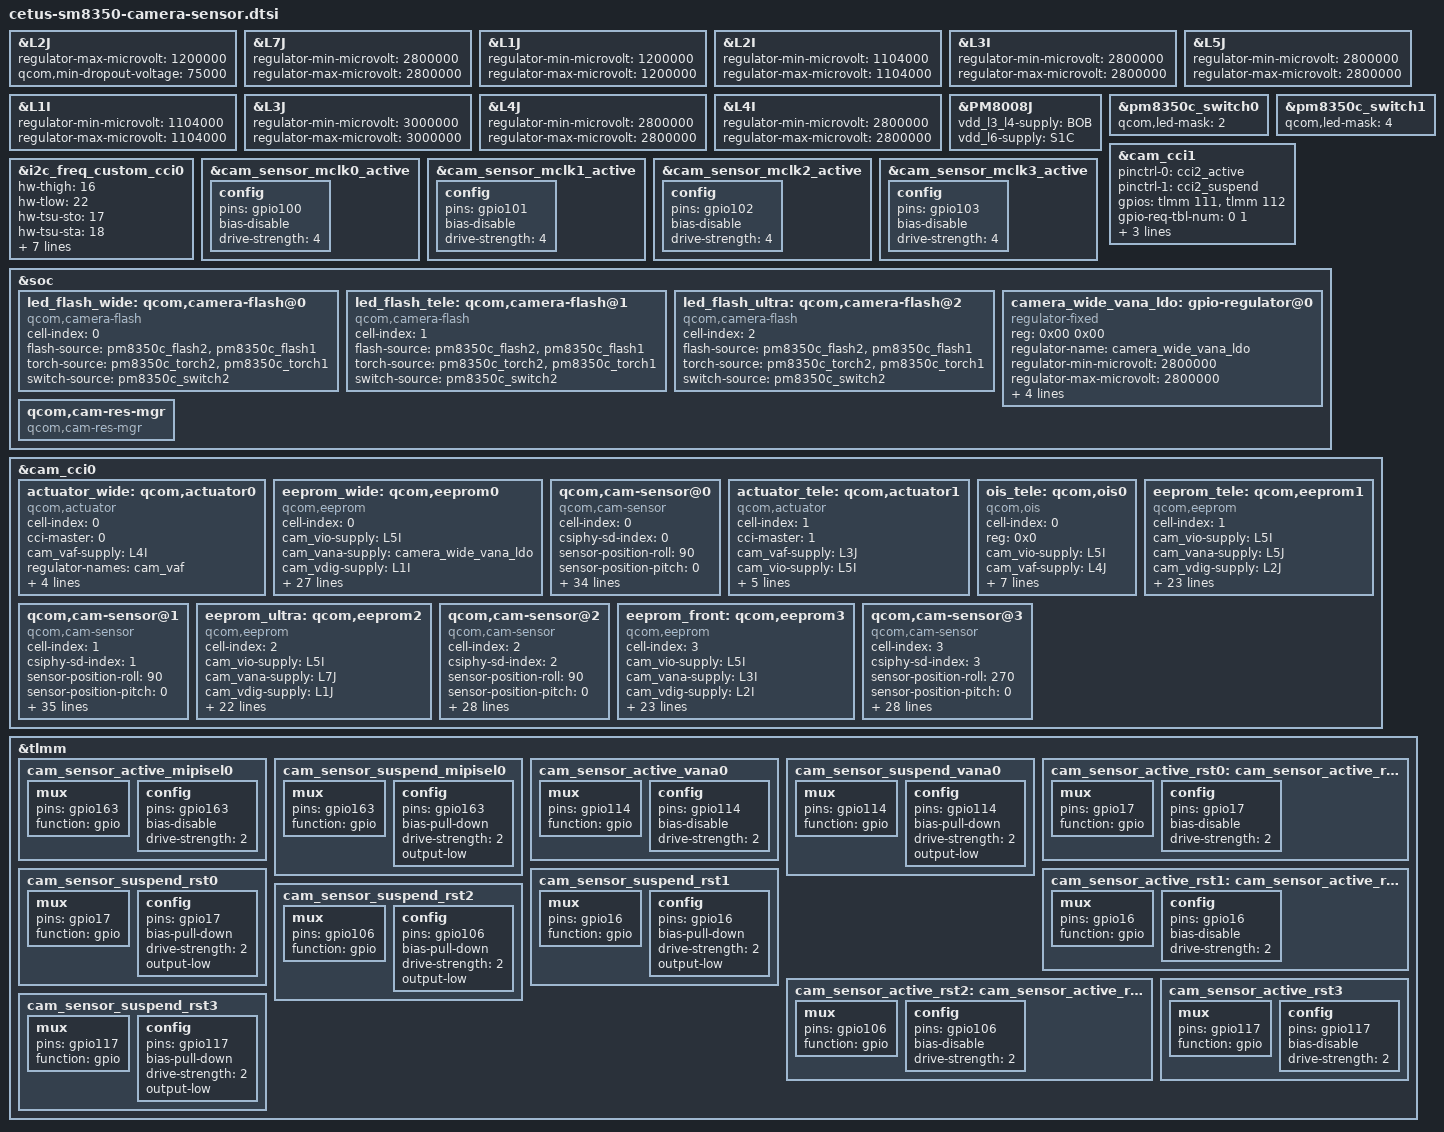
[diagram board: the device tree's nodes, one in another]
#include <dt-bindings/clock/qcom,camcc-lahaina.h>

&L2J {
	regulator-max-microvolt = <1200000>;
	qcom,min-dropout-voltage = <75000>;
};

&L7J {
	regulator-min-microvolt = <2800000>;
	regulator-max-microvolt = <2800000>;
};

&L1J {
	regulator-min-microvolt = <1200000>;
	regulator-max-microvolt = <1200000>;
};

&L2I {
	regulator-min-microvolt = <1104000>;
	regulator-max-microvolt = <1104000>;
};

&L3I {
	regulator-min-microvolt = <2800000>;
	regulator-max-microvolt = <2800000>;
};

&L5J {
	regulator-min-microvolt = <2800000>;
	regulator-max-microvolt = <2800000>;
};

&L1I {
	regulator-min-microvolt = <1104000>;
	regulator-max-microvolt = <1104000>;
};

&L3J {
	regulator-min-microvolt = <3000000>;
	regulator-max-microvolt = <3000000>;
};

&L4J {
	regulator-min-microvolt = <2800000>;
	regulator-max-microvolt = <2800000>;
};

&L4I {
	regulator-min-microvolt = <2800000>;
	regulator-max-microvolt = <2800000>;
};

&PM8008J {
	vdd_l3_l4-supply = <&BOB>;
	vdd_l6-supply = <&S1C>;
};

&pm8350c_switch0 {
	qcom,led-mask = <2>; /* Channels 1 & 2 */
};

&pm8350c_switch1 {
	qcom,led-mask = <4>; /* Channels 2 & 3 */
};

&cam_cci1 {
	pinctrl-0 = <&cci2_active>;
	pinctrl-1 = <&cci2_suspend>;
	gpios = <&tlmm 111 0>,
		<&tlmm 112 0>;
	gpio-req-tbl-num = <0 1>;
	gpio-req-tbl-flags = <1 1>;
	gpio-req-tbl-label = "CCI_I2C_DATA2",
			"CCI_I2C_CLK2";
};

&i2c_freq_custom_cci0 {
	hw-thigh = <16>;
	hw-tlow = <22>;
	hw-tsu-sto = <17>;
	hw-tsu-sta = <18>;
	hw-thd-dat = <16>;
	hw-thd-sta = <15>;
	hw-tbuf = <24>;
	hw-scl-stretch-en = <1>;
	hw-trdhld = <3>;
	hw-tsp = <3>;
	cci-clk-src = <37500000>;
	status = "ok";
};

&cam_sensor_mclk0_active {
	/* MCLK0 */
	config {
		pins = "gpio100";
		bias-disable; /* No PULL */
		drive-strength = <4>; /* 4 MA */
	};
};

&cam_sensor_mclk1_active {
	/* MCLK1 */
	config {
		pins = "gpio101";
		bias-disable; /* No PULL */
		drive-strength = <4>; /* 4 MA */
	};
};

&cam_sensor_mclk2_active {
	/* MCLK2 */
	config {
		pins = "gpio102";
		bias-disable; /* No PULL */
		drive-strength = <4>; /* 4 MA */
	};
};

&cam_sensor_mclk3_active {
	/* MCLK3 */
	config {
		pins = "gpio103";
		bias-disable; /* No PULL */
		drive-strength = <4>; /* 4 MA */
	};
};

&soc {
	led_flash_wide: qcom,camera-flash@0 {
		cell-index = <0>;
		compatible = "qcom,camera-flash";
		flash-source = <&pm8350c_flash2 &pm8350c_flash1>;
		torch-source = <&pm8350c_torch2 &pm8350c_torch1>;
		switch-source = <&pm8350c_switch2>;
		status = "ok";
	};

	led_flash_tele: qcom,camera-flash@1 {
		cell-index = <1>;
		compatible = "qcom,camera-flash";
		flash-source = <&pm8350c_flash2 &pm8350c_flash1>;
		torch-source = <&pm8350c_torch2 &pm8350c_torch1>;
		switch-source = <&pm8350c_switch2>;
		status = "ok";
	};

	led_flash_ultra: qcom,camera-flash@2 {
		cell-index = <2>;
		compatible = "qcom,camera-flash";
		flash-source = <&pm8350c_flash2 &pm8350c_flash1>;
		torch-source = <&pm8350c_torch2 &pm8350c_torch1>;
		switch-source = <&pm8350c_switch2>;
		status = "ok";
	};

	camera_wide_vana_ldo: gpio-regulator@0 {
		compatible = "regulator-fixed";
		reg = <0x00 0x00>;
		regulator-name = "camera_wide_vana_ldo";
		regulator-min-microvolt = <2800000>;
		regulator-max-microvolt = <2800000>;
		regulator-enable-ramp-delay = <135>;
		enable-active-high;
		gpio = <&tlmm 114 0>;
		vin-supply = <&pm8350c_bob>;
	};

	qcom,cam-res-mgr {
		compatible = "qcom,cam-res-mgr";
		//shared-gpios = <409>;
		//pinctrl-names = "cam_res_mgr_default", "cam_res_mgr_suspend";
		//pinctrl-0 = <&cam_sensor_mclk1_active>;
		//pinctrl-1 = <&cam_sensor_mclk1_suspend>;
		//status = "ok";
	};
};

&cam_cci0 {
	actuator_wide: qcom,actuator0 {
		cell-index = <0>;
		compatible = "qcom,actuator";
		cci-master = <0>;
		cam_vaf-supply = <&L4I>;
		regulator-names = "cam_vaf";
		rgltr-cntrl-support;
		rgltr-min-voltage = <2800000>;
		rgltr-max-voltage = <2800000>;
		rgltr-load-current = <100000>;
		status = "ok";
	};

	eeprom_wide: qcom,eeprom0 {
		cell-index = <0>;
		compatible = "qcom,eeprom";
		cam_vio-supply = <&L5I>;
		cam_vana-supply = <&camera_wide_vana_ldo>;
		cam_vdig-supply = <&L1I>;
		cam_clk-supply = <&cam_cc_titan_top_gdsc>;
		regulator-names = "cam_vio", "cam_vana", "cam_vdig","cam_clk";
		rgltr-cntrl-support;
		pwm-switch;
		rgltr-min-voltage = <1800000 2800000 1104000 0>;
		rgltr-max-voltage = <1800000 2800000 1104000 0>;
		rgltr-load-current = <120000 2000000 1200000 0>;
		gpio-no-mux = <0>;
		pinctrl-names = "cam_default", "cam_suspend";
		pinctrl-0 = <&cam_sensor_mclk0_active
			&cam_sensor_active_rst0
			&cam_sensor_active_mipisel0>;
		pinctrl-1 = <&cam_sensor_mclk0_suspend
			&cam_sensor_suspend_rst0
			&cam_sensor_suspend_mipisel0>;
		gpios = <&tlmm 100 0>,
			<&tlmm 17 0>,
			<&tlmm 163 0>;
		gpio-reset = <1>;
		gpio-custom1 = <2>;
		gpio-req-tbl-num = <0 1 2>;
		gpio-req-tbl-flags = <1 0 0>;
		gpio-req-tbl-label = "CAMIF_MCLK0",
				"CAM_RESET0",
				"CAM_MIPISEL0";
		sensor-mode = <0>;
		cci-master = <0>;
		status = "ok";
		clocks = <&clock_camcc CAM_CC_MCLK0_CLK>;
		clock-names = "cam_clk";
		clock-cntl-level = "nominal";
		clock-rates = <19200000>;
	};

	/*  Wide sensor */
	qcom,cam-sensor@0 {
		cell-index = <0>;
		compatible = "qcom,cam-sensor";
		csiphy-sd-index = <0>;
		sensor-position-roll = <90>;
		sensor-position-pitch = <0>;
		sensor-position-yaw = <180>;
		actuator-src = <&actuator_wide>;
		eeprom-src = <&eeprom_wide>;
		led-flash-src = <&led_flash_wide>;
		cam_vio-supply = <&L5I>;
		cam_vana-supply = <&camera_wide_vana_ldo>;
		cam_vdig-supply = <&L1I>;
		cam_clk-supply = <&cam_cc_titan_top_gdsc>;
		regulator-names = "cam_vio", "cam_vana", "cam_vdig","cam_clk";
		rgltr-cntrl-support;
		pwm-switch;
		rgltr-min-voltage = <1800000 2800000 1104000 0>;
		rgltr-max-voltage = <1800000 2800000 1104000 0>;
		rgltr-load-current = <120000 2000000 1200000 0>;
		gpio-no-mux = <0>;
		pinctrl-names = "cam_default", "cam_suspend";
		pinctrl-0 = <&cam_sensor_mclk0_active
			&cam_sensor_active_rst0
			&cam_sensor_active_mipisel0>;
		pinctrl-1 = <&cam_sensor_mclk0_suspend
			&cam_sensor_suspend_rst0
			&cam_sensor_suspend_mipisel0>;
		gpios = <&tlmm 100 0>,
			<&tlmm 17 0>,
			<&tlmm 163 0>;
		gpio-reset = <1>;
		gpio-custom1 = <2>;
		gpio-req-tbl-num = <0 1 2>;
		gpio-req-tbl-flags = <1 0 0>;
		gpio-req-tbl-label = "CAMIF_MCLK0",
				"CAM_RESET0",
				"CAM_MIPISEL0";
		sensor-mode = <0>;
		cci-master = <0>;
		status = "ok";
		clocks = <&clock_camcc CAM_CC_MCLK0_CLK>;
		clock-names = "cam_clk";
		clock-cntl-level = "nominal";
		clock-rates = <19200000>;
	};

	actuator_tele: qcom,actuator1 {
		cell-index = <1>;
		compatible = "qcom,actuator";
		cci-master = <1>;
		cam_vaf-supply = <&L3J>;
		cam_vio-supply = <&L5I>;
		regulator-names = "cam_vaf", "cam_vio";
		rgltr-cntrl-support;
		rgltr-min-voltage = <3000000 1800000>;
		rgltr-max-voltage = <3000000 1800000>;
		rgltr-load-current = <300000 10000>;
		status = "ok";
	};

	ois_tele: qcom,ois0 {
		cell-index = <0>;
		reg = <0x0>;
		compatible = "qcom,ois";
		cam_vio-supply = <&L5I>;
		cam_vaf-supply = <&L4J>;
		cam_clk-supply = <&cam_cc_titan_top_gdsc>;
		regulator-names = "cam_vio", "cam_vaf", "cam_clk";
		rgltr-min-voltage = <1800000 2800000 0>;
		rgltr-max-voltage = <1800000 2800000 0>;
		rgltr-load-current = <10000 280000 0>;
		//use-shared-clk;
		//gpio-no-mux = <0>;
		//gpios = <&tlmm 101 0>;
		//gpio-req-tbl-num = <0>;
		//gpio-req-tbl-flags = <1>;
		//gpio-req-tbl-label = "CAMIF_MCLK1";
		//clocks = <&clock_camcc CAM_CC_MCLK1_CLK>;
		//clock-names = "cam_clk";
		//clock-cntl-level = "nominal";
		//clock-rates = <19200000>;
		rgltr-cntrl-support;
		cci-master = <1>;
		status = "ok";
	};

	eeprom_tele: qcom,eeprom1 {
		cell-index = <1>;
		compatible = "qcom,eeprom";
		cam_vio-supply = <&L5I>;
		cam_vana-supply = <&L5J>;
		cam_vdig-supply = <&L2J>;
		cam_clk-supply = <&cam_cc_titan_top_gdsc>;
		regulator-names = "cam_vio", "cam_vana", "cam_vdig","cam_clk";
		rgltr-cntrl-support;
		pwm-switch;
		rgltr-min-voltage = <1800000 2800000 1200000 0>;
		rgltr-max-voltage = <1800000 2800000 1200000 0>;
		rgltr-load-current = <120000 80000 1200000 0>;
		gpio-no-mux = <0>;
		pinctrl-names = "cam_default", "cam_suspend";
		pinctrl-0 = <&cam_sensor_mclk1_active
			&cam_sensor_active_rst1>;
		pinctrl-1 = <&cam_sensor_mclk1_suspend
			&cam_sensor_suspend_rst1>;
		gpios = <&tlmm 101 0>,
			<&tlmm 16 0>;
		gpio-reset = <1>;
		gpio-req-tbl-num = <0 1>;
		gpio-req-tbl-flags = <1 0>;
		gpio-req-tbl-label = "CAMIF_MCLK1",
				"CAM_RESET1";
		sensor-mode = <0>;
		cci-master = <1>;
		status = "ok";
		clocks = <&clock_camcc CAM_CC_MCLK1_CLK>;
		clock-names = "cam_clk";
		clock-cntl-level = "nominal";
		clock-rates = <19200000>;
	};

	/*  Tele sensor */
	qcom,cam-sensor@1 {
		cell-index = <1>;
		compatible = "qcom,cam-sensor";
		csiphy-sd-index = <1>;
		sensor-position-roll = <90>;
		sensor-position-pitch = <0>;
		sensor-position-yaw = <180>;
		eeprom-src = <&eeprom_tele>;
		actuator-src = <&actuator_tele>;
		ois-src = <&ois_tele>;
		led-flash-src = <&led_flash_tele>;
		cam_vio-supply = <&L5I>;
		cam_vana-supply = <&L5J>;
		cam_vdig-supply = <&L2J>;
		cam_vaf-supply = <&L4J>;
		cam_clk-supply = <&cam_cc_titan_top_gdsc>;
		//cam_bob-supply = <&pm8350c_bob>;
		regulator-names = "cam_vio", "cam_vana", "cam_vdig", "cam_vaf",
				 "cam_clk";
		rgltr-cntrl-support;
		pwm-switch;
		rgltr-min-voltage = <1800000 2800000 1200000 2800000 0>;
		rgltr-max-voltage = <1800000 2800000 1200000 2800000 0>;
		rgltr-load-current = <120000 80000 1200000 280000 0>;
		gpio-no-mux = <0>;
		//use-shared-clk;
		pinctrl-names = "cam_default", "cam_suspend";
		pinctrl-0 = <&cam_sensor_active_rst1
                        &cam_sensor_mclk1_active>;
		pinctrl-1 = <&cam_sensor_suspend_rst1
                        &cam_sensor_mclk1_suspend>;
		gpios = <&tlmm 101 0>,
			<&tlmm 16 0>;
		gpio-reset = <1>;
		gpio-req-tbl-num = <0 1>;
		gpio-req-tbl-flags = <1 0>;
		gpio-req-tbl-label = "CAMIF_MCLK1",
				"CAM_RESET1";
		sensor-mode = <0>;
		cci-master = <1>;
		status = "ok";
		clocks = <&clock_camcc CAM_CC_MCLK1_CLK>;
		clock-names = "cam_clk";
		clock-cntl-level = "nominal";
		clock-rates = <19200000>;
	};

	eeprom_ultra: qcom,eeprom2 {
		cell-index = <2>;
		compatible = "qcom,eeprom";
		cam_vio-supply = <&L5I>;
		cam_vana-supply = <&L7J>;
		cam_vdig-supply = <&L1J>;
		cam_clk-supply = <&cam_cc_titan_top_gdsc>;
		regulator-names = "cam_vio", "cam_vdig","cam_vana", "cam_clk";
		rgltr-cntrl-support;
		rgltr-min-voltage = <1800000 1200000 2800000 0>;
		rgltr-max-voltage = <1800000 1200000 2800000 0>;
		rgltr-load-current = <120000 1056000 80000 0>;
		gpio-no-mux = <0>;
		pinctrl-names = "cam_default", "cam_suspend";
		pinctrl-0 = <&cam_sensor_mclk2_active
			&cam_sensor_active_rst2>;
		pinctrl-1 = <&cam_sensor_mclk2_suspend
			&cam_sensor_suspend_rst2>;
		gpios = <&tlmm 102 0>,
			<&tlmm 106 0>;
		gpio-reset = <1>;
		gpio-req-tbl-num = <0 1>;
		gpio-req-tbl-flags = <1 0>;
		gpio-req-tbl-label = "CAMIF_MCLK2",
				"CAM_RESET2";
		sensor-mode = <0>;
		cci-master = <1>;
		status = "ok";
		clocks = <&clock_camcc CAM_CC_MCLK2_CLK>;
		clock-names = "cam_clk";
		clock-cntl-level = "nominal";
		clock-rates = <19200000>;
	};

	/*  Ultra sensor */
	qcom,cam-sensor@2 {
		cell-index = <2>;
		compatible = "qcom,cam-sensor";
		csiphy-sd-index = <2>;
		sensor-position-roll = <90>;
		sensor-position-pitch = <0>;
		sensor-position-yaw = <180>;
		eeprom-src = <&eeprom_ultra>;
		led-flash-src = <&led_flash_ultra>;
		cam_vana-supply = <&L7J>;
		cam_vio-supply = <&L5I>;
		cam_vdig-supply = <&L1J>;
		cam_clk-supply = <&cam_cc_titan_top_gdsc>;
		regulator-names = "cam_vio", "cam_vdig","cam_vana", "cam_clk";
		rgltr-cntrl-support;
		rgltr-min-voltage = <1800000 1200000 2800000 0>;
		rgltr-max-voltage = <1800000 1200000 2800000 0>;
		rgltr-load-current = <120000 1056000 80000 0>;
		gpio-no-mux = <0>;
		pinctrl-names = "cam_default", "cam_suspend";
		pinctrl-0 = <&cam_sensor_mclk2_active
			&cam_sensor_active_rst2>;
		pinctrl-1 = <&cam_sensor_mclk2_suspend
			&cam_sensor_suspend_rst2>;
		gpios = <&tlmm 102 0>,
			<&tlmm 106 0>;
		gpio-reset = <1>;
		gpio-req-tbl-num = <0 1>;
		gpio-req-tbl-flags = <1 0>;
		gpio-req-tbl-label = "CAMIF_MCLK2",
				"CAM_RESET2";
		sensor-mode = <0>;
		cci-master = <1>;
		status = "ok";
		clocks = <&clock_camcc CAM_CC_MCLK2_CLK>;
		clock-names = "cam_clk";
		clock-cntl-level = "nominal";
		clock-rates = <19200000>;
	};

	eeprom_front: qcom,eeprom3 {
		cell-index = <3>;
		compatible = "qcom,eeprom";
		cam_vio-supply = <&L5I>;
		cam_vana-supply = <&L3I>;
		cam_vdig-supply = <&L2I>;
		cam_clk-supply = <&cam_cc_titan_top_gdsc>;
		regulator-names = "cam_vio", "cam_vana", "cam_vdig","cam_clk";
		rgltr-cntrl-support;
		pwm-switch;
		rgltr-min-voltage = <1800000 2800000 1104000 0>;
		rgltr-max-voltage = <1800000 2800000 1104000 0>;
		rgltr-load-current = <120000 80000 1200000 0>;
		gpio-no-mux = <0>;
		pinctrl-names = "cam_default", "cam_suspend";
		pinctrl-0 = <&cam_sensor_mclk3_active
			&cam_sensor_active_rst3>;
		pinctrl-1 = <&cam_sensor_mclk3_suspend
			&cam_sensor_suspend_rst3>;
		gpios = <&tlmm 103 0>,
			<&tlmm 117 0>;
		gpio-reset = <1>;
		gpio-req-tbl-num = <0 1>;
		gpio-req-tbl-flags = <1 0>;
		gpio-req-tbl-label = "CAMIF_MCLK3",
				"CAM_RESET3";
		sensor-mode = <0>;
		cci-master = <0>;
		status = "ok";
		clocks = <&clock_camcc CAM_CC_MCLK3_CLK>;
		clock-names = "cam_clk";
		clock-cntl-level = "nominal";
		clock-rates = <19200000>;
};

	/* Front sensor */
	qcom,cam-sensor@3 {
		cell-index = <3>;
		compatible = "qcom,cam-sensor";
		csiphy-sd-index = <3>;
		sensor-position-roll = <270>;
		sensor-position-pitch = <0>;
		sensor-position-yaw = <0>;
		eeprom-src = <&eeprom_front>;
		cam_vio-supply = <&L5I>;
		cam_vana-supply = <&L3I>;
		cam_vdig-supply = <&L2I>;
		cam_clk-supply = <&cam_cc_titan_top_gdsc>;
		regulator-names = "cam_vio", "cam_vana", "cam_vdig","cam_clk";
		rgltr-cntrl-support;
		pwm-switch;
		rgltr-min-voltage = <1800000 2800000 1104000 0>;
		rgltr-max-voltage = <1800000 2800000 1104000 0>;
		rgltr-load-current = <120000 80000 1200000 0>;
		gpio-no-mux = <0>;
		pinctrl-names = "cam_default", "cam_suspend";
		pinctrl-0 = <&cam_sensor_mclk3_active
			     &cam_sensor_active_rst3>;
		pinctrl-1 = <&cam_sensor_mclk3_suspend
			     &cam_sensor_suspend_rst3>;
		gpios = <&tlmm 103 0>,
			<&tlmm 117 0>;
		gpio-reset = <1>;
		gpio-req-tbl-num = <0 1>;
		gpio-req-tbl-flags = <1 0>;
		gpio-req-tbl-label = "CAMIF_MCLK3",
				"CAM_RESET3";
		sensor-mode = <0>;
		cci-master = <0>;
		status = "ok";
		clocks = <&clock_camcc CAM_CC_MCLK3_CLK>;
		clock-names = "cam_clk";
		clock-cntl-level = "nominal";
		clock-rates = <19200000>;
	};
};


&tlmm {
	cam_sensor_active_mipisel0: cam_sensor_active_mipisel0 {
		mux {
			pins = "gpio163";
			function = "gpio";
		};

		config {
			pins = "gpio163";
			bias-disable; /* No PULL */
			drive-strength = <2>; /* 2 MA */
		};
	};

	cam_sensor_suspend_mipisel0: cam_sensor_suspend_mipisel0 {
		mux {
			pins = "gpio163";
			function = "gpio";
		};

		config {
			pins = "gpio163";
			bias-pull-down; /* PULL DOWN */
			drive-strength = <2>; /* 2 MA */
			output-low;
		};
	};

	cam_sensor_active_vana0: cam_sensor_active_vana0 {
		mux {
			pins = "gpio114";
			function = "gpio";
		};

		config {
			pins = "gpio114";
			bias-disable; /* No PULL */
			drive-strength = <2>; /* 2 MA */
		};
	};

	cam_sensor_suspend_vana0: cam_sensor_suspend_vana0 {
		mux {
			pins = "gpio114";
			function = "gpio";
		};

		config {
			pins = "gpio114";
			bias-pull-down; /* PULL DOWN */
			drive-strength = <2>; /* 2 MA */
			output-low;
		};
	};

	cam_sensor_active_rst0: cam_sensor_active_rstr0 {
		/* RESET REAR */
		mux {
			pins = "gpio17";
			function = "gpio";
		};

		config {
			pins = "gpio17";
			bias-disable; /* No PULL */
			drive-strength = <2>; /* 2 MA */
		};
	};

	cam_sensor_suspend_rst0: cam_sensor_suspend_rst0 {
		/* RESET REAR */
		mux {
			pins = "gpio17";
			function = "gpio";
		};

		config {
			pins = "gpio17";
			bias-pull-down; /* PULL DOWN */
			drive-strength = <2>; /* 2 MA */
			output-low;
		};
	};

	cam_sensor_active_rst1: cam_sensor_active_rstr1 {
		/* RESET REAR */
		mux {
			pins = "gpio16";
			function = "gpio";
		};

		config {
			pins = "gpio16";
			bias-disable; /* No PULL */
			drive-strength = <2>; /* 2 MA */
		};
	};

	cam_sensor_suspend_rst1: cam_sensor_suspend_rst1 {
		/* RESET REAR */
		mux {
			pins = "gpio16";
			function = "gpio";
		};

		config {
			pins = "gpio16";
			bias-pull-down; /* PULL DOWN */
			drive-strength = <2>; /* 2 MA */
			output-low;
		};
	};

	cam_sensor_active_rst2: cam_sensor_active_rstr2 {
		/* RESET REAR */
		mux {
			pins = "gpio106";
			function = "gpio";
		};

		config {
			pins = "gpio106";
			bias-disable; /* No PULL */
			drive-strength = <2>; /* 2 MA */
		};
	};

	cam_sensor_suspend_rst2: cam_sensor_suspend_rst2 {
		/* RESET REAR */
		mux {
			pins = "gpio106";
			function = "gpio";
		};

		config {
			pins = "gpio106";
			bias-pull-down; /* PULL DOWN */
			drive-strength = <2>; /* 2 MA */
			output-low;
		};
	};

	cam_sensor_active_rst3: cam_sensor_active_rst3 {
		/* RESET FRONT */
		mux {
			pins = "gpio117";
			function = "gpio";
		};

		config {
			pins = "gpio117";
			bias-disable; /* No PULL */
			drive-strength = <2>; /* 2 MA */
		};
	};

	cam_sensor_suspend_rst3: cam_sensor_suspend_rst3 {
		/* RESET FRONT */
		mux {
			pins = "gpio117";
			function = "gpio";
		};

		config {
			pins = "gpio117";
			bias-pull-down; /* PULL DOWN */
			drive-strength = <2>; /* 2 MA */
			output-low;
		};
	};
};
